# TLSR8278 register map
File version: 0.1
Registers are 8-bit, access not given, no defined reset value unless marked. A register's access mark holds for its fields unless they carry their own. Offsets are from the block's base; [hi:lo] are bit positions; {n}, {i} and the like mark numbered series.

## TIMER — Auto-generated from section 'timer'
Base 0x00800620
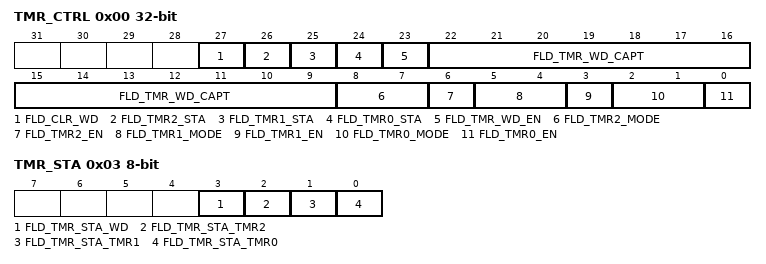
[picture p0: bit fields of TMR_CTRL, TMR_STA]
0x00 TMR_CTRL 32-bit — Auto-generated from tmr_ctrl; aliases: TMR_CTRL16, TMR_CTRL8
  [27] FLD_CLR_WD, [26] FLD_TMR2_STA, [25] FLD_TMR1_STA, [24] FLD_TMR0_STA, [23] FLD_TMR_WD_EN, [22:9] FLD_TMR_WD_CAPT, [8:7] FLD_TMR2_MODE, [6] FLD_TMR2_EN, [5:4] FLD_TMR1_MODE, [3] FLD_TMR1_EN, [2:1] FLD_TMR0_MODE, [0] FLD_TMR0_EN
0x03 TMR_STA — Auto-generated from tmr_sta
  [3] FLD_TMR_STA_WD, [2] FLD_TMR_STA_TMR2, [1] FLD_TMR_STA_TMR1, [0] FLD_TMR_STA_TMR0
{0x4+4i} TMR{i}_CAPT 32-bit (i=0..2) — Auto-generated from tmr{i}_capt
{0x10+4i} TMR{i}_TICK 32-bit (i=0..2) — Auto-generated from tmr{i}_tick

## IRQ — Auto-generated from section 'irq'
Base 0x00800640
0x00 IRQ_MASK 32-bit — Auto-generated from irq_mask
0x03 IRQ_EN — Auto-generated from irq_en
0x04 IRQ_PRI 32-bit — Auto-generated from irq_pri
0x08 IRQ_SRC 32-bit — Auto-generated from irq_src
  [31:24] FLD_IRQ_EN, [22] FLD_IRQ_GPIO_RISC1_EN, [21] FLD_IRQ_GPIO_RISC0_EN, [20] FLD_IRQ_SYSTEM_TIMER, [19] FLD_IRQ_PM_EN, [18] FLD_IRQ_GPIO_EN, [17] FLD_IRQ_USB_RST_EN, [16] FLD_IRQ_USB_250US_EN, [15] FLD_IRQ_PKE_EN, [14] FLD_IRQ_SW_PWM_EN, [13] FLD_IRQ_ZB_RT_EN, [12] FLD_IRQ_EP_DATA_EN, [12] FLD_IRQ_IRQ4_EN, [11] FLD_IRQ_SET_INTF_EN, [10] FLD_IRQ_EP0_STA_EN, [9] FLD_IRQ_EP0_DAT_EN, [8] FLD_IRQ_EP0_SETUP_EN, [7] FLD_IRQ_HOST_CMD_EN, [7] FLD_IRQ_MIX_CMD_EN, [6] FLD_IRQ_UART_EN, [5] FLD_IRQ_DAM_FIFO_EN, [4] FLD_IRQ_DMA_EN, [3] FLD_IRQ_USB_PWDN_EN, [2] FLD_IRQ_TMR2_EN, [1] FLD_IRQ_TMR1_EN, [0] FLD_IRQ_TMR0_EN
0x0A IRQ_SRC3 — Auto-generated from irq_src3

## SYSTEM_TIMER — Auto-generated from section 'system timer'
Base 0x00800740
0x00 SYSTEM_TICK 32-bit — Auto-generated from system_tick
0x04 SYSTEM_TICK_IRQ_LEVEL 32-bit — Auto-generated from system_tick_irq_level
0x08 SYSTEM_IRQ_MASK — Auto-generated from system_irq_mask
0x09 SYSTEM_CAL_IRQ — Auto-generated from system_cal_irq
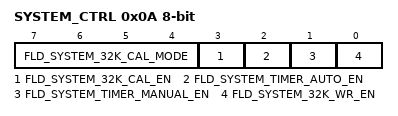
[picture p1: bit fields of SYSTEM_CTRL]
0x0A SYSTEM_CTRL — Auto-generated from system_ctrl
  [7:4] FLD_SYSTEM_32K_CAL_MODE, [3] FLD_SYSTEM_32K_CAL_EN, [2] FLD_SYSTEM_TIMER_AUTO_EN, [1] FLD_SYSTEM_TIMER_MANUAL_EN, [0] FLD_SYSTEM_32K_WR_EN
0x0B SYSTEM_STATUS — Auto-generated from system_status
  [6] FLD_SYSTEM_32K_TIMER_BUSY, [5] FLD_SYSTEM_32K_TIMER_CLEAR_RD, [5] FLD_SYSTEM_32K_TIMER_UPDATE_RD, [3] FLD_SYSTEM_32K_TIMER_SYNC_TRIG, [4:3] FLD_SYSTEM_STATE_MACHINE_STATUS, [2] FLD_SYSTEM_CMD_SET_TRIG, [1] FLD_SYSTEM_CMD_SYNC_TRIG, [0] FLD_SYSTEM_TIMER_STATUS
0x0C SYSTEM_32K_TICK_WT 32-bit — Auto-generated from system_32k_tick_wt
0x10 SYSTEM_32K_TICK_RD 32-bit — Auto-generated from system_32k_tick_rd
0x14 SYSTEM_32K_TICK_CAL 32-bit — Auto-generated from system_32k_tick_cal

## PWM — Auto-generated from section 'pwm'
Base 0x00800780
0x00 PWM_ENABLE — Auto-generated from pwm_enable
0x01 PWM0_ENABLE — Auto-generated from pwm0_enable
0x02 PWM_CLK — Auto-generated from pwm_clk
0x03 PWM0_MODE — Auto-generated from pwm0_mode
0x04 PWM_INVERT — Auto-generated from pwm_invert
0x05 PWM_N_INVERT — Auto-generated from pwm_n_invert
0x06 PWM_POL — Auto-generated from pwm_pol
0x2C PWM0_PULSE_NUM 16-bit — Auto-generated from pwm0_pulse_num
0x30 PWM_IRQ_MASK — Auto-generated from pwm_irq_mask
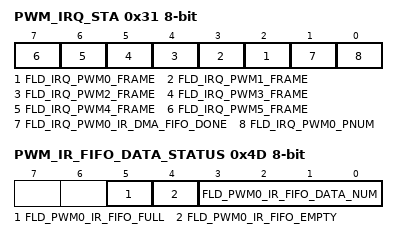
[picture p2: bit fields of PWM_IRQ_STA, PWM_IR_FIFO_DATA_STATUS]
0x31 PWM_IRQ_STA — Auto-generated from pwm_irq_sta
  [n+2] FLD_IRQ_PWM{n}_FRAME (n=0..5), [1] FLD_IRQ_PWM0_IR_DMA_FIFO_DONE, [0] FLD_IRQ_PWM0_PNUM
0x32 PWM0_FIFO_MODE_IRQ_MASK — Auto-generated from pwm0_fifo_mode_irq_mask
  [0] FLD_PWM0_IRQ_IR_FIFO_EN
0x33 PWM0_FIFO_MODE_IRQ_STA — Auto-generated from pwm0_fifo_mode_irq_sta
  [0] FLD_PWM0_IRQ_IR_FIFO_CNT
0x4C PWM_IR_FIFO_IRQ_TRIG_LEVEL — Auto-generated from pwm_ir_fifo_irq_trig_level
0x4D PWM_IR_FIFO_DATA_STATUS — Auto-generated from pwm_ir_fifo_data_status
  [5] FLD_PWM0_IR_FIFO_FULL, [4] FLD_PWM0_IR_FIFO_EMPTY, [3:0] FLD_PWM0_IR_FIFO_DATA_NUM
0x4E PWM_IR_CLR_FIFO_DATA — Auto-generated from pwm_ir_clr_fifo_data
  [0] FLD_PWM0_IR_FIFO_CLR_DATA
